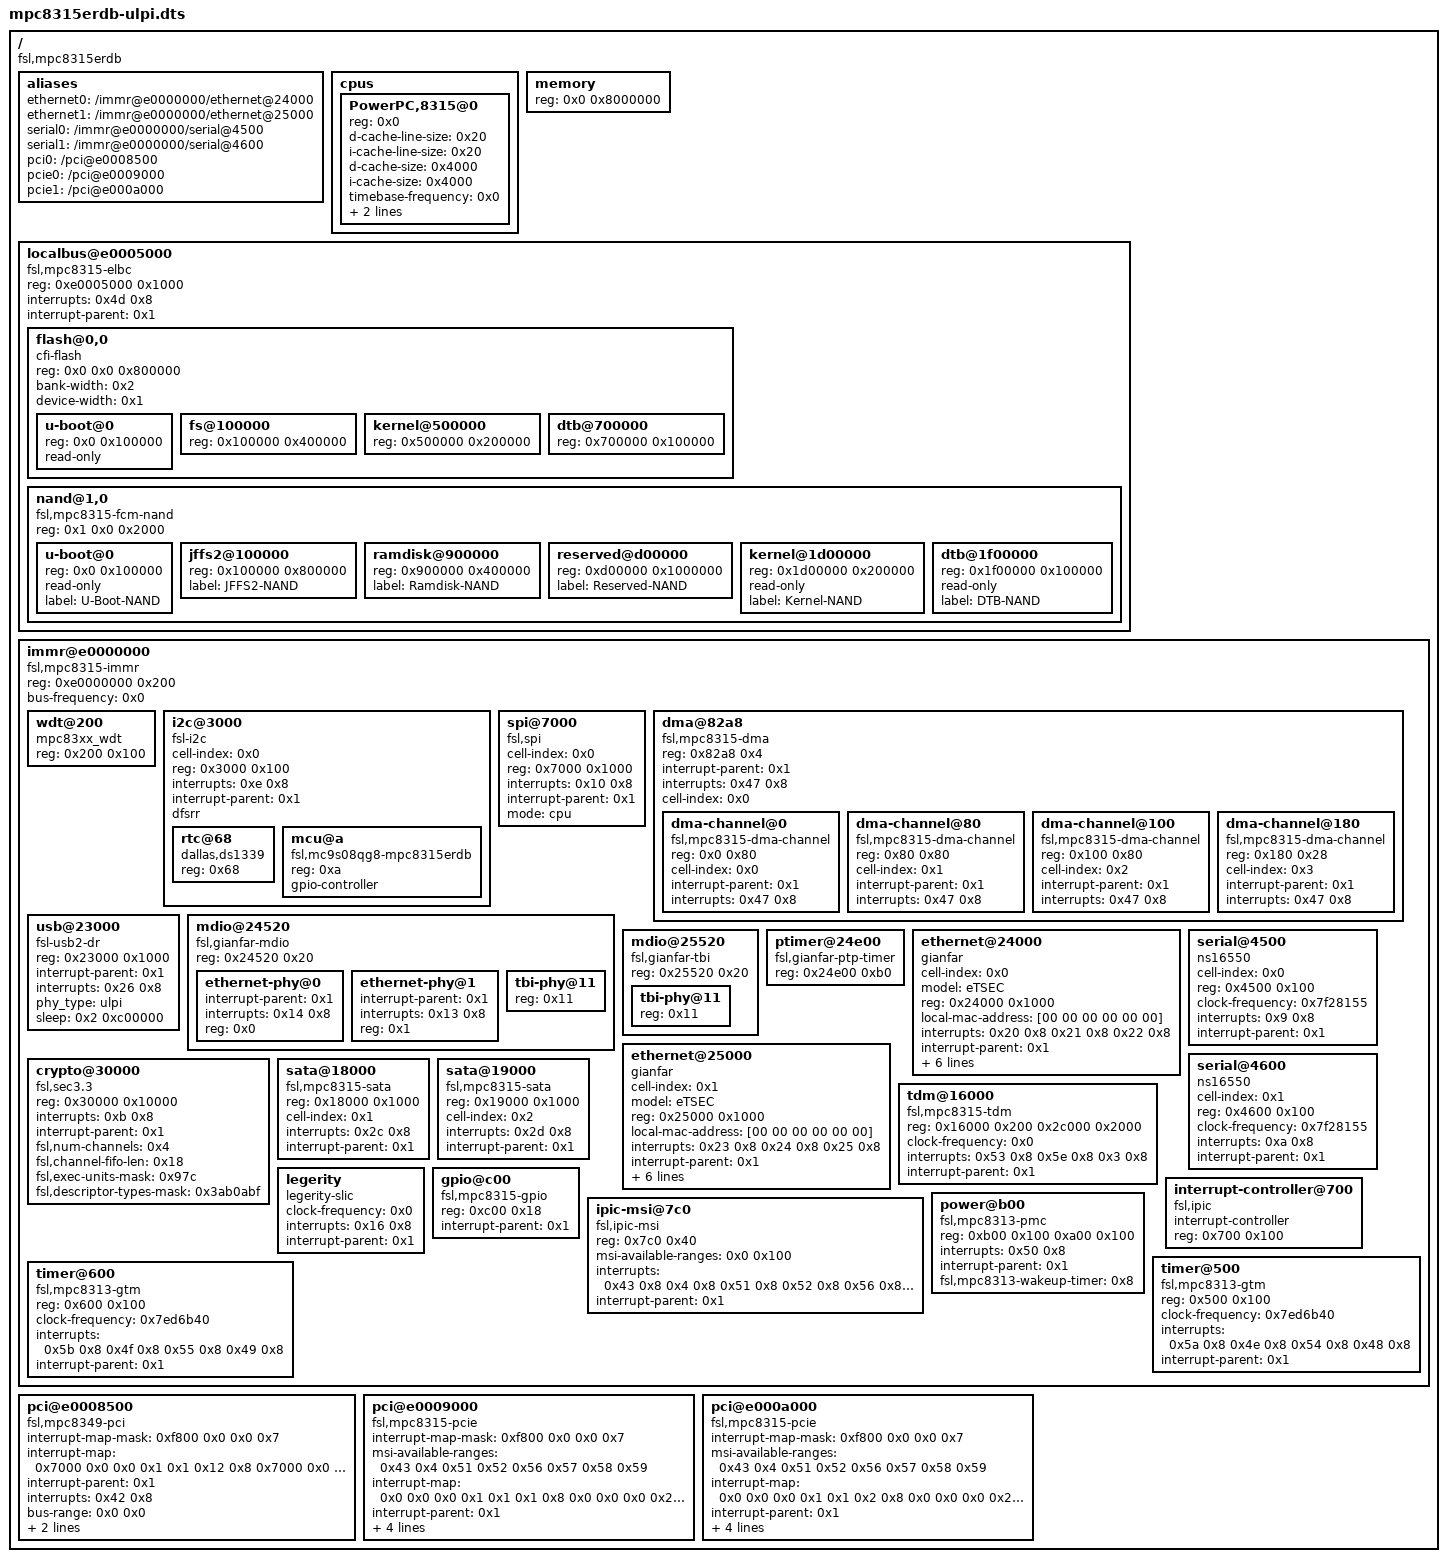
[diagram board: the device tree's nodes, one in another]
/dts-v1/;

/ {
	compatible = "fsl,mpc8315erdb";
	#address-cells = <0x1>;
	#size-cells = <0x1>;

	aliases {
		ethernet0 = "/immr@e0000000/ethernet@24000";
		ethernet1 = "/immr@e0000000/ethernet@25000";
		serial0 = "/immr@e0000000/serial@4500";
		serial1 = "/immr@e0000000/serial@4600";
		pci0 = "/pci@e0008500";
		pcie0 = "/pci@e0009000";
		pcie1 = "/pci@e000a000";
	};

	cpus {
		#address-cells = <0x1>;
		#size-cells = <0x0>;

		PowerPC,8315@0 {
			device_type = "cpu";
			reg = <0x0>;
			d-cache-line-size = <0x20>;
			i-cache-line-size = <0x20>;
			d-cache-size = <0x4000>;
			i-cache-size = <0x4000>;
			timebase-frequency = <0x0>;
			bus-frequency = <0x0>;
			clock-frequency = <0x0>;
		};
	};

	memory {
		device_type = "memory";
		reg = <0x0 0x8000000>;
	};

	localbus@e0005000 {
		#address-cells = <0x2>;
		#size-cells = <0x1>;
		compatible = "fsl,mpc8315-elbc", "fsl,elbc", "simple-bus";
		reg = <0xe0005000 0x1000>;
		interrupts = <0x4d 0x8>;
		interrupt-parent = <0x1>;
		ranges = <0x0 0x0 0xfe000000 0x800000 0x1 0x0 0xe0600000 0x2000 0x2 0x0 0xf0000000 0x20000 0x3 0x0 0xfa000000 0x8000>;

		flash@0,0 {
			#address-cells = <0x1>;
			#size-cells = <0x1>;
			compatible = "cfi-flash";
			reg = <0x0 0x0 0x800000>;
			bank-width = <0x2>;
			device-width = <0x1>;

			u-boot@0 {
				reg = <0x0 0x100000>;
				read-only;
			};

			fs@100000 {
				reg = <0x100000 0x400000>;
			};

			kernel@500000 {
				reg = <0x500000 0x200000>;
			};

			dtb@700000 {
				reg = <0x700000 0x100000>;
			};
		};

		nand@1,0 {
			#address-cells = <0x1>;
			#size-cells = <0x1>;
			compatible = "fsl,mpc8315-fcm-nand", "fsl,elbc-fcm-nand";
			reg = <0x1 0x0 0x2000>;

			u-boot@0 {
				reg = <0x0 0x100000>;
				read-only;
				label = "U-Boot-NAND";
			};

			jffs2@100000 {
				reg = <0x100000 0x800000>;
				label = "JFFS2-NAND";
			};

			ramdisk@900000 {
				reg = <0x900000 0x400000>;
				label = "Ramdisk-NAND";
			};

			reserved@d00000 {
				reg = <0xd00000 0x1000000>;
				label = "Reserved-NAND";
			};

			kernel@1d00000 {
				reg = <0x1d00000 0x200000>;
				read-only;
				label = "Kernel-NAND";
			};

			dtb@1f00000 {
				reg = <0x1f00000 0x100000>;
				read-only;
				label = "DTB-NAND";
			};
		};
	};

	immr@e0000000 {
		#address-cells = <0x1>;
		#size-cells = <0x1>;
		device_type = "soc";
		compatible = "fsl,mpc8315-immr", "simple-bus";
		ranges = <0x0 0xe0000000 0x100000>;
		reg = <0xe0000000 0x200>;
		bus-frequency = <0x0>;

		wdt@200 {
			device_type = "watchdog";
			compatible = "mpc83xx_wdt";
			reg = <0x200 0x100>;
		};

		i2c@3000 {
			#address-cells = <0x1>;
			#size-cells = <0x0>;
			cell-index = <0x0>;
			compatible = "fsl-i2c";
			reg = <0x3000 0x100>;
			interrupts = <0xe 0x8>;
			interrupt-parent = <0x1>;
			dfsrr;

			rtc@68 {
				compatible = "dallas,ds1339";
				reg = <0x68>;
			};

			mcu@a {
				#gpio-cells = <0x2>;
				compatible = "fsl,mc9s08qg8-mpc8315erdb", "fsl,mcu-mpc8349emitx";
				reg = <0xa>;
				gpio-controller;
			};
		};

		spi@7000 {
			cell-index = <0x0>;
			compatible = "fsl,spi";
			reg = <0x7000 0x1000>;
			interrupts = <0x10 0x8>;
			interrupt-parent = <0x1>;
			mode = "cpu";
		};

		dma@82a8 {
			#address-cells = <0x1>;
			#size-cells = <0x1>;
			compatible = "fsl,mpc8315-dma", "fsl,elo-dma";
			reg = <0x82a8 0x4>;
			ranges = <0x0 0x8100 0x1a8>;
			interrupt-parent = <0x1>;
			interrupts = <0x47 0x8>;
			cell-index = <0x0>;

			dma-channel@0 {
				compatible = "fsl,mpc8315-dma-channel", "fsl,elo-dma-channel";
				reg = <0x0 0x80>;
				cell-index = <0x0>;
				interrupt-parent = <0x1>;
				interrupts = <0x47 0x8>;
			};

			dma-channel@80 {
				compatible = "fsl,mpc8315-dma-channel", "fsl,elo-dma-channel";
				reg = <0x80 0x80>;
				cell-index = <0x1>;
				interrupt-parent = <0x1>;
				interrupts = <0x47 0x8>;
			};

			dma-channel@100 {
				compatible = "fsl,mpc8315-dma-channel", "fsl,elo-dma-channel";
				reg = <0x100 0x80>;
				cell-index = <0x2>;
				interrupt-parent = <0x1>;
				interrupts = <0x47 0x8>;
			};

			dma-channel@180 {
				compatible = "fsl,mpc8315-dma-channel", "fsl,elo-dma-channel";
				reg = <0x180 0x28>;
				cell-index = <0x3>;
				interrupt-parent = <0x1>;
				interrupts = <0x47 0x8>;
			};
		};

		usb@23000 {
			compatible = "fsl-usb2-dr";
			reg = <0x23000 0x1000>;
			#address-cells = <0x1>;
			#size-cells = <0x0>;
			interrupt-parent = <0x1>;
			interrupts = <0x26 0x8>;
			phy_type = "ulpi";
			sleep = <0x2 0xc00000>;
		};

		mdio@24520 {
			#address-cells = <0x1>;
			#size-cells = <0x0>;
			compatible = "fsl,gianfar-mdio";
			reg = <0x24520 0x20>;

			ethernet-phy@0 {
				interrupt-parent = <0x1>;
				interrupts = <0x14 0x8>;
				reg = <0x0>;
				device_type = "ethernet-phy";
				linux,phandle = <0x4>;
			};

			ethernet-phy@1 {
				interrupt-parent = <0x1>;
				interrupts = <0x13 0x8>;
				reg = <0x1>;
				device_type = "ethernet-phy";
				linux,phandle = <0x7>;
			};

			tbi-phy@11 {
				reg = <0x11>;
				device_type = "tbi-phy";
				linux,phandle = <0x3>;
			};
		};

		mdio@25520 {
			#address-cells = <0x1>;
			#size-cells = <0x0>;
			compatible = "fsl,gianfar-tbi";
			reg = <0x25520 0x20>;

			tbi-phy@11 {
				reg = <0x11>;
				device_type = "tbi-phy";
				linux,phandle = <0x6>;
			};
		};

		ptimer@24e00 {
			compatible = "fsl,gianfar-ptp-timer";
			reg = <0x24e00 0xb0>;
			linux,phandle = <0x5>;
		};

		ethernet@24000 {
			cell-index = <0x0>;
			device_type = "network";
			model = "eTSEC";
			compatible = "gianfar";
			reg = <0x24000 0x1000>;
			local-mac-address = [00 00 00 00 00 00];
			interrupts = <0x20 0x8 0x21 0x8 0x22 0x8>;
			interrupt-parent = <0x1>;
			tbi-handle = <0x3>;
			phy-handle = <0x4>;
			sleep = <0x2 0xc0000000>;
			fsl,magic-packet;
			fsl,lossless-flow-ctrl = <0x0>;
			ptimer-handle = <0x5>;
		};

		ethernet@25000 {
			cell-index = <0x1>;
			device_type = "network";
			model = "eTSEC";
			compatible = "gianfar";
			reg = <0x25000 0x1000>;
			local-mac-address = [00 00 00 00 00 00];
			interrupts = <0x23 0x8 0x24 0x8 0x25 0x8>;
			interrupt-parent = <0x1>;
			tbi-handle = <0x6>;
			phy-handle = <0x7>;
			sleep = <0x2 0x30000000>;
			fsl,magic-packet;
			fsl,lossless-flow-ctrl = <0x0>;
			ptimer-handle = <0x5>;
		};

		serial@4500 {
			cell-index = <0x0>;
			device_type = "serial";
			compatible = "ns16550";
			reg = <0x4500 0x100>;
			clock-frequency = <0x7f28155>;
			interrupts = <0x9 0x8>;
			interrupt-parent = <0x1>;
		};

		serial@4600 {
			cell-index = <0x1>;
			device_type = "serial";
			compatible = "ns16550";
			reg = <0x4600 0x100>;
			clock-frequency = <0x7f28155>;
			interrupts = <0xa 0x8>;
			interrupt-parent = <0x1>;
		};

		crypto@30000 {
			compatible = "fsl,sec3.3", "fsl,sec3.1", "fsl,sec3.0", "fsl,sec2.4", "fsl,sec2.2", "fsl,sec2.1", "fsl,sec2.0";
			reg = <0x30000 0x10000>;
			interrupts = <0xb 0x8>;
			interrupt-parent = <0x1>;
			fsl,num-channels = <0x4>;
			fsl,channel-fifo-len = <0x18>;
			fsl,exec-units-mask = <0x97c>;
			fsl,descriptor-types-mask = <0x3ab0abf>;
		};

		sata@18000 {
			compatible = "fsl,mpc8315-sata", "fsl,pq-sata";
			reg = <0x18000 0x1000>;
			cell-index = <0x1>;
			interrupts = <0x2c 0x8>;
			interrupt-parent = <0x1>;
		};

		sata@19000 {
			compatible = "fsl,mpc8315-sata", "fsl,pq-sata";
			reg = <0x19000 0x1000>;
			cell-index = <0x2>;
			interrupts = <0x2d 0x8>;
			interrupt-parent = <0x1>;
		};

		tdm@16000 {
			device_type = "tdm";
			compatible = "fsl,mpc8315-tdm";
			reg = <0x16000 0x200 0x2c000 0x2000>;
			clock-frequency = <0x0>;
			interrupts = <0x53 0x8 0x5e 0x8 0x3 0x8>;
			interrupt-parent = <0x1>;
		};

		legerity {
			device_type = "slic";
			compatible = "legerity-slic";
			clock-frequency = <0x0>;
			interrupts = <0x16 0x8>;
			interrupt-parent = <0x1>;
		};

		gpio@c00 {
			device_type = "gpio";
			compatible = "fsl,mpc8315-gpio";
			reg = <0xc00 0x18>;
			interrupt-parent = <0x1>;
		};

		interrupt-controller@700 {
			compatible = "fsl,ipic";
			interrupt-controller;
			#address-cells = <0x0>;
			#interrupt-cells = <0x2>;
			reg = <0x700 0x100>;
			device_type = "ipic";
			linux,phandle = <0x1>;
		};

		ipic-msi@7c0 {
			compatible = "fsl,ipic-msi";
			reg = <0x7c0 0x40>;
			msi-available-ranges = <0x0 0x100>;
			interrupts = <0x43 0x8 0x4 0x8 0x51 0x8 0x52 0x8 0x56 0x8 0x57 0x8 0x58 0x8 0x59 0x8>;
			interrupt-parent = <0x1>;
		};

		power@b00 {
			compatible = "fsl,mpc8313-pmc", "fsl,mpc8349-pmc";
			reg = <0xb00 0x100 0xa00 0x100>;
			interrupts = <0x50 0x8>;
			interrupt-parent = <0x1>;
			fsl,mpc8313-wakeup-timer = <0x8>;
			linux,phandle = <0x2>;
		};

		timer@500 {
			compatible = "fsl,mpc8313-gtm", "fsl,gtm";
			reg = <0x500 0x100>;
			clock-frequency = <0x7ed6b40>;
			interrupts = <0x5a 0x8 0x4e 0x8 0x54 0x8 0x48 0x8>;
			interrupt-parent = <0x1>;
			linux,phandle = <0x8>;
		};

		timer@600 {
			compatible = "fsl,mpc8313-gtm", "fsl,gtm";
			reg = <0x600 0x100>;
			clock-frequency = <0x7ed6b40>;
			interrupts = <0x5b 0x8 0x4f 0x8 0x55 0x8 0x49 0x8>;
			interrupt-parent = <0x1>;
		};
	};

	pci@e0008500 {
		interrupt-map-mask = <0xf800 0x0 0x0 0x7>;
		interrupt-map = <0x7000 0x0 0x0 0x1 0x1 0x12 0x8 0x7000 0x0 0x0 0x2 0x1 0x12 0x8 0x7000 0x0 0x0 0x3 0x1 0x12 0x8 0x7000 0x0 0x0 0x4 0x1 0x12 0x8 0x7800 0x0 0x0 0x1 0x1 0x11 0x8 0x7800 0x0 0x0 0x2 0x1 0x11 0x8 0x7800 0x0 0x0 0x3 0x1 0x11 0x8 0x7800 0x0 0x0 0x4 0x1 0x11 0x8 0x8000 0x0 0x0 0x1 0x1 0x30 0x8 0x8000 0x0 0x0 0x2 0x1 0x11 0x8 0x8000 0x0 0x0 0x3 0x1 0x30 0x8 0x8000 0x0 0x0 0x4 0x1 0x11 0x8>;
		interrupt-parent = <0x1>;
		interrupts = <0x42 0x8>;
		bus-range = <0x0 0x0>;
		ranges = <0x2000000 0x0 0x90000000 0x90000000 0x0 0x10000000 0x42000000 0x0 0x80000000 0x80000000 0x0 0x10000000 0x1000000 0x0 0x0 0xe0300000 0x0 0x100000>;
		clock-frequency = <0x3f940aa>;
		#interrupt-cells = <0x1>;
		#size-cells = <0x2>;
		#address-cells = <0x3>;
		reg = <0xe0008500 0x100 0xe0008300 0x8>;
		compatible = "fsl,mpc8349-pci";
		device_type = "pci";
	};

	pci@e0009000 {
		interrupt-map-mask = <0xf800 0x0 0x0 0x7>;
		msi-available-ranges = <0x43 0x4 0x51 0x52 0x56 0x57 0x58 0x59>;
		interrupt-map = <0x0 0x0 0x0 0x1 0x1 0x1 0x8 0x0 0x0 0x0 0x2 0x1 0x1 0x8 0x0 0x0 0x0 0x3 0x1 0x1 0x8 0x0 0x0 0x0 0x4 0x1 0x1 0x8>;
		interrupt-parent = <0x1>;
		interrupts = <0x1 0x8>;
		bus-range = <0x0 0x0>;
		ranges = <0x2000000 0x0 0xa0000000 0xa0000000 0x0 0x10000000 0x1000000 0x0 0x0 0xb1000000 0x0 0x800000>;
		clock-frequency = <0x0>;
		#interrupt-cells = <0x1>;
		#size-cells = <0x2>;
		#address-cells = <0x3>;
		reg = <0xe0009000 0x1000 0xb0000000 0x1000000>;
		compatible = "fsl,mpc8315-pcie";
		device_type = "pci";
	};

	pci@e000a000 {
		interrupt-map-mask = <0xf800 0x0 0x0 0x7>;
		msi-available-ranges = <0x43 0x4 0x51 0x52 0x56 0x57 0x58 0x59>;
		interrupt-map = <0x0 0x0 0x0 0x1 0x1 0x2 0x8 0x0 0x0 0x0 0x2 0x1 0x2 0x8 0x0 0x0 0x0 0x3 0x1 0x2 0x8 0x0 0x0 0x0 0x4 0x1 0x2 0x8>;
		interrupt-parent = <0x1>;
		interrupts = <0x2 0x8>;
		bus-range = <0x0 0x0>;
		ranges = <0x2000000 0x0 0xc0000000 0xc0000000 0x0 0x10000000 0x1000000 0x0 0x0 0xd1000000 0x0 0x800000>;
		clock-frequency = <0x0>;
		#interrupt-cells = <0x1>;
		#size-cells = <0x2>;
		#address-cells = <0x3>;
		reg = <0xe000a000 0x1000 0xd0000000 0x1000000>;
		compatible = "fsl,mpc8315-pcie";
		device_type = "pci";
	};
};
